# AT32F426xx_v2 register map
Vendor: Keil; Series: AT32F426; File version: 1.0
CPU: CM4 r0p1, little endian, no MPU, FPU, 4 interrupt priority bits
Registers are 32-bit, read-write, reset 0x0 unless marked. A register's access mark holds for its fields unless they carry their own. Offsets are from the block's base; [hi:lo] are bit positions.

## USART1 — Universal synchronous asynchronous receiver transmitter
Base 0x40013800
Same registers: USART2 0x40004400
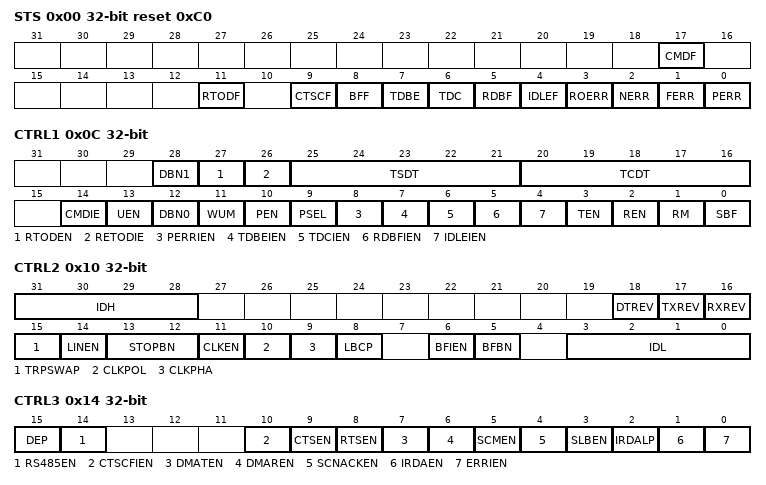
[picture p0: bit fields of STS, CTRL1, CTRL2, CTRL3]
0x00 STS reset 0xC0 — Status register
  [17] CMDF ro — Character match detect flag
  [11] RTODF ro — Receiver time out detection flag
  [9] CTSCF — CTS change flag
  [8] BFF — Break frame flag
  [7] TDBE ro — Transmit data buffer empty
  [6] TDC — Transmit data complete
  [5] RDBF — Receive data buffer full
  [4] IDLEF ro — IDLE flag
  [3] ROERR ro — Receiver overflow error
  [2] NERR ro — Noise error
  [1] FERR ro — Framing error
  [0] PERR ro — Parity error
0x04 DT — Data register
  [8:0] DT — Data value
0x08 BAUDR — Baud rate register
  [15:0] DIV — Division
0x0C CTRL1 — Control register 1
  [28] DBN1 — high bit for Data bit num
  [27] RTODEN — Receiver time out detection enable
  [26] RETODIE — Receiver time out detection interrupt enable
  [25:21] TSDT — transmit start delay time
  [20:16] TCDT — transmit complete delay time
  [14] CMDIE — Character match detection interrupt enable
  [13] UEN — USART enable
  [12] DBN0 — low bit for Data bit num
  [11] WUM — Wake up mode
  [10] PEN — Parity enable
  [9] PSEL — Parity selection
  [8] PERRIEN — PERR interrupt enable
  [7] TDBEIEN — TDBE interrupt enable
  [6] TDCIEN — TDC interrupt enable
  [5] RDBFIEN — RDBF interrupt enable
  [4] IDLEIEN — IDLE interrupt enable
  [3] TEN — Transmitter enable
  [2] REN — Receiver enable
  [1] RM — Receiver mute
  [0] SBF — Send break frame
0x10 CTRL2 — Control register 2
  [31:28] IDH — bit 7-4 for usart identification
  [18] DTREV — DT register polarity reverse
  [17] TXREV — TX polarity reverse
  [16] RXREV — RX polarity reverse
  [15] TRPSWAP — Transmit receive pin swap
  [14] LINEN — LIN mode enable
  [13:12] STOPBN — STOP bit num
  [11] CLKEN — Clock enable
  [10] CLKPOL — Clock polarity
  [9] CLKPHA — Clock phase
  [8] LBCP — Last bit clock pulse
  [6] BFIEN — Break frame interrupt enable
  [5] BFBN — Break frame bit num
  [3:0] IDL — bit 3-0 for usart identification
0x14 CTRL3 — Control register 3
  [15] DEP — DE polarity selection
  [14] RS485EN — RS485 enable
  [10] CTSCFIEN — CTSCF interrupt enable
  [9] CTSEN — CTS enable
  [8] RTSEN — RTS enable
  [7] DMATEN — DMA transmitter enable
  [6] DMAREN — DMA receiver enable
  [5] SCMEN — Smartcard mode enable
  [4] SCNACKEN — Smartcard NACK enable
  [3] SLBEN — Single line bidirectional half-duplex enable
  [2] IRDALP — IrDA low-power mode
  [1] IRDAEN — IrDA enable
  [0] ERRIEN — Error interrupt enable
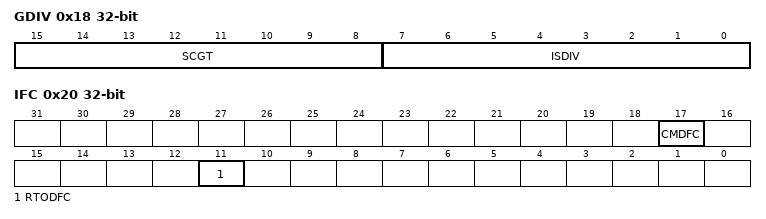
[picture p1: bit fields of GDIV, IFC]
0x18 GDIV — Guard time and division register
  [15:8] SCGT — Smart card guard time value
  [7:0] ISDIV — IrDA/smartcard division value
0x1C RTOV — Receiver time out value register
  [23:0] RTOV — Receiver time out value
0x20 IFC wo — Interrupt flag clear register
  [17] CMDFC — Character match flag clear
  [11] RTODFC — Receiver time out detection flag clear

## DAC — Digital to analog converter
Base 0x40007400
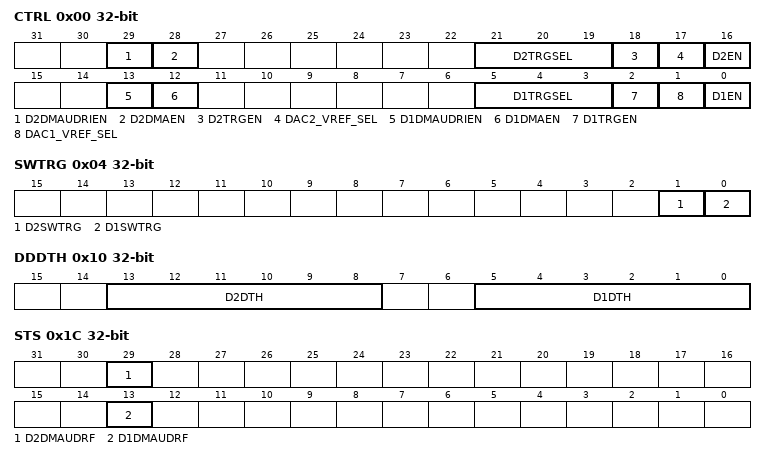
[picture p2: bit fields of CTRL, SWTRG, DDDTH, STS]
0x00 CTRL — Control register (DAC_CTRL)
  [29] D2DMAUDRIEN — DAC2 DMA underrun interrupt enable
  [28] D2DMAEN — DAC2 DMA enable
  [21:19] D2TRGSEL — DAC2 trigger selection
  [18] D2TRGEN — DAC2 trigger enable
  [17] DAC2_VREF_SEL — DAC2 reference voltage switch
  [16] D2EN — DAC2 enable
  [13] D1DMAUDRIEN — DAC1 DMA underrun interrupt enable
  [12] D1DMAEN — DAC1 DMA enable
  [5:3] D1TRGSEL — DAC1 trigger selection
  [2] D1TRGEN — DAC1 trigger enable
  [1] DAC1_VREF_SEL — DAC1 reference voltage switch
  [0] D1EN — DAC1 enable
0x04 SWTRG wo — DAC software trigger register(DAC_SWTRIGR)
  [1] D2SWTRG — DAC2 software trigger
  [0] D1SWTRG — DAC1 software trigger
0x08 D1DTH — DAC1 6-bit right-aligned data holding register(DAC_D1DTH)
  [5:0] D1DTH — DAC1 6-bit right-aligned data
0x0C D2DTH — DAC2 6-bit right aligned data holding register (DAC_D2DTH)
  [5:0] D2DTH — DAC2 6-bit right-aligned data
0x10 DDDTH — Dual DAC 6-bit right-aligned data holding register (DAC_DDDTH), Bits 31:14 Reserved, Bits 7:6 Reserved
  [13:8] D2DTH — DAC2 6-bit right-aligned data
  [5:0] D1DTH — DAC1 6-bit right-aligned data
0x14 D1ODT ro — DAC1 data output register (DAC_D1ODT)
  [5:0] D1ODT — DAC1 data output
0x18 D2ODT ro — DAC2 data output register (DAC_D2ODT)
  [5:0] D2ODT — DAC2 data output
0x1C STS — DAC status register(DAC_STS)
  [29] D2DMAUDRF — DAC2 DMA underrun flag
  [13] D1DMAUDRF — DAC1 DMA underrun flag
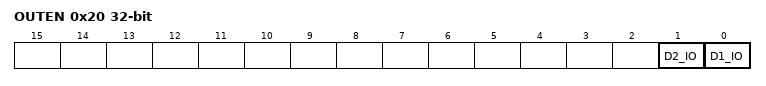
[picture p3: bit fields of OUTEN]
0x20 OUTEN — DAC output enable register(DAC_OUTEN)
  [1] D2_IO — DAC2 output to GPIO
  [0] D1_IO — DAC1 output to GPIO
